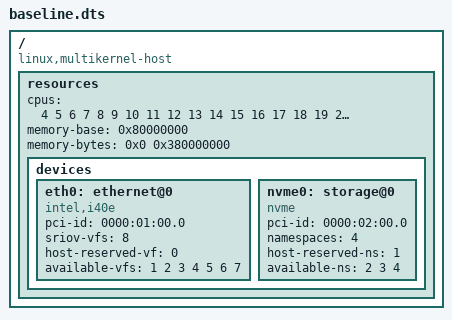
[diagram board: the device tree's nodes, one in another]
/*
 * Baseline Device Tree Example
 *
 * This file defines the hardware resources available for allocation to
 * kernel instances. It contains ONLY resources - no instances.
 *
 * Usage:
 *   kerf init --input=baseline.dts --apply
 *
 * Instances are created at runtime via overlays:
 *   kerf create --name=web-server --cpus=4-7 --memory=2GB
 *   kerf create --name=database --cpus=8-15 --memory=8GB
 */

/multikernel-v1/;

/ {
    compatible = "linux,multikernel-host";

    resources {
        cpus = <4 5 6 7 8 9 10 11 12 13 14 15 
                16 17 18 19 20 21 22 23 24 25 26 27 28 29 30 31>;
        memory-base = <0x80000000>;
        memory-bytes = <0x0 0x380000000>;  // 14GB
        
        devices {
            eth0: ethernet@0 {
                compatible = "intel,i40e";
                pci-id = "0000:01:00.0";
                sriov-vfs = <8>;
                host-reserved-vf = <0>;
                available-vfs = <1 2 3 4 5 6 7>;
            };
            
            nvme0: storage@0 {
                compatible = "nvme";
                pci-id = "0000:02:00.0";
                namespaces = <4>;
                host-reserved-ns = <1>;
                available-ns = <2 3 4>;
            };
        };
    };
};

